# mcr_me18 register map
Registers are access not given, no defined reset value unless marked. A register's access mark holds for its fields unless they carry their own. Offsets are from the block's base; lines under a group give offsets from that group; [hi:lo] are bit positions; {n}, {i} and the like mark numbered series; 'fields as' and 'values as' point back to an identical list; <NAME> marks a mode.

## Memory map
0x40006C00 MCR size 0x400 — Misc Control.

## MCR — Misc Control.
Base 0x40006C00
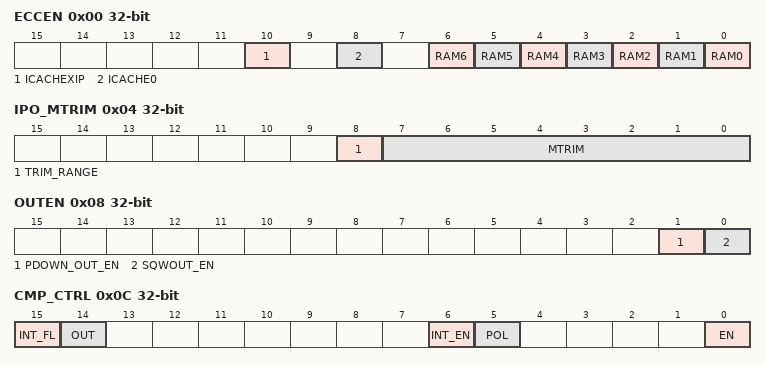
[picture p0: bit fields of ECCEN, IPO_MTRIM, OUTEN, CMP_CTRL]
0x00 ECCEN — ECC Enable Register
  [all] fields
    0=dis (disabled.); 1=en (enabled.)
  [10] ICACHEXIP — ECC ICACHE XIP Enable.
  [8] ICACHE0 — ECC ICACHE0 Enable.
  [n] RAM{n} (n=0..6) — ECC System RAM{n} Enable.
0x04 IPO_MTRIM — IPO Manual Register
  [8] TRIM_RANGE — Trim Range Select.
  [7:0] MTRIM — Manual Trim Value.
0x08 OUTEN — Output Enable Register
  [1] PDOWN_OUT_EN — Power Down Output Enable.
  [0] SQWOUT_EN — Square Wave Output Enable.
0x0C CMP_CTRL — Comparator Control Register.
  [15] INT_FL — IRQ Flag
  [14] OUT — Comparator Output State.
  [6] INT_EN — IRQ Enable.
  [5] POL — Polarity Select
  [0] EN — Comparator Enable.
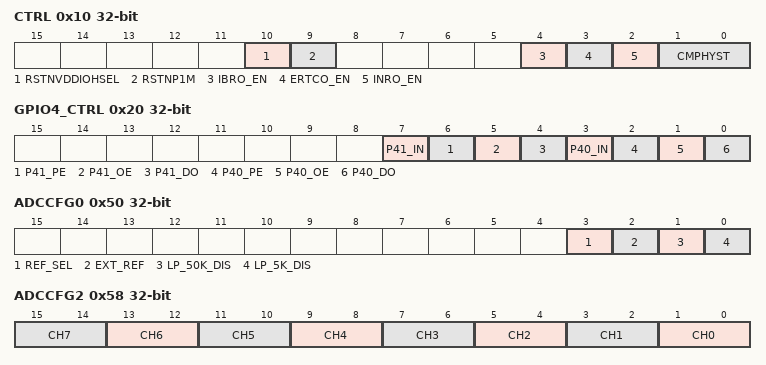
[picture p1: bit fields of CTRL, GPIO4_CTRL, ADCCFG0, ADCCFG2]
0x10 CTRL — Miscellaneous Control Register.
  [10] RSTNVDDIOHSEL — RSTNVFFIOHSEL
  [9] RSTNP1M
  [4] IBRO_EN — IBRO Enable.
  [3] ERTCO_EN — ERTCO Enable.
  [2] INRO_EN — INRO Enable.
  [1:0] CMPHYST — Comparator HYST.
0x20 GPIO4_CTRL — GPIO4 Pin Control Register.
  [7] P41_IN — GPIO4 Pin 1 Input Status.
  [6] P41_PE — GPIO4 Pin 1 Pull-up Enable.
  [5] P41_OE — GPIO4 Pin 1 Output Enable.
  [4] P41_DO — GPIO4 Pin 1 Data Output.
  [3] P40_IN — GPIO4 Pin 0 Input Status.
  [2] P40_PE — GPIO4 Pin 0 Pull-up Enable.
  [1] P40_OE — GPIO4 Pin 0 Output Enable.
  [0] P40_DO — GPIO4 Pin 0 Data Output.
0x40 CWD0 — Code Word Data0
  [31:0] data — Code word Data0 the register retains its value while vregi supply present
0x44 CWD1 — Code Word Data1
  fields as CWD0
0x50 ADCCFG0 — ADC Config 0
  [3] REF_SEL — Internal Reference Select Option
  [2] EXT_REF — External Reference Select Option
  [1] LP_50K_DIS — Disable 50K divider optionin low power modes
  [0] LP_5K_DIS — Disable 5K divider optionin low power modes
0x54 ADCCFG1 — ADC Config 1
  [12:0] CHX_PU_DYN — ADC PU dynamic control
0x58 ADCCFG2 — ADC Config 2
  [all] fields
    0=div1; 1=div2_5k (5k ohom); 2=div2_50k (50k ohom)
  [2n+1:2n] CH{n} (n=0..7) — Divider option for ADC input channel {n}
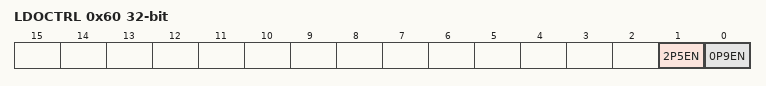
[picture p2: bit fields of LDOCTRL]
0x60 LDOCTRL — LDO Control
  [1] 2P5EN — LDO 2.5V Enable
  [0] 0P9EN — LDO 0.9V Enable
